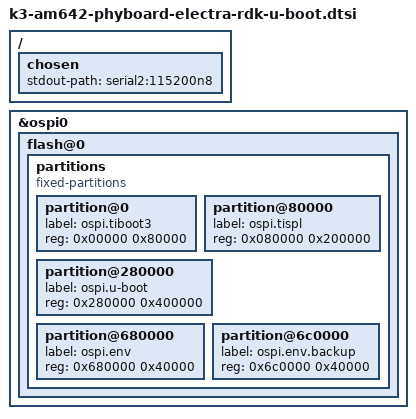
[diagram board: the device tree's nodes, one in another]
// SPDX-License-Identifier: GPL-2.0
/*
 * Copyright (C) 2021 PHYTEC America, LLC - https://www.phytec.com
 * Author: Matt McKee <mmckee@phytec.com>
 *
 * Copyright (C) 2022 - 2024 PHYTEC Messtechnik GmbH
 * Author: Wadim Egorov <w.egorov@phytec.de>
 *
 * Product homepage:
 * https://www.phytec.com/product/phycore-am64x
 */

#include "k3-am642-phycore-som-binman.dtsi"
#include "k3-am642-u-boot.dtsi"

/ {
	chosen {
		stdout-path = "serial2:115200n8";
	};
};

&ospi0 {
	flash@0 {
		partitions {
			compatible = "fixed-partitions";
			#address-cells = <1>;
			#size-cells = <1>;

			partition@0 {
				label = "ospi.tiboot3";
				reg = <0x00000 0x80000>;
			};
			partition@80000 {
				label = "ospi.tispl";
				reg = <0x080000 0x200000>;
			};
			partition@280000 {
				label = "ospi.u-boot";
				reg = <0x280000 0x400000>;
			};
			partition@680000 {
				label = "ospi.env";
				reg = <0x680000 0x40000>;
			};
			partition@6c0000 {
				label = "ospi.env.backup";
				reg = <0x6c0000 0x40000>;
			};
		};
	};
};
